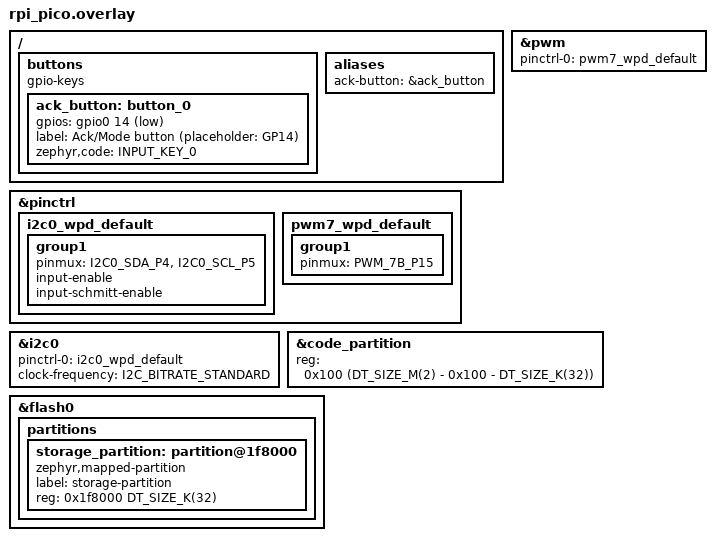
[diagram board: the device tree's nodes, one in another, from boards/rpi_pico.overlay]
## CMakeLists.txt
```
# Objetivo: arquivo de build da aplicação Zephyr.
#
# Responsabilidade: declarar os fontes compilados nesta etapa e os include paths
# compartilhados (include/ na raiz do repositório, ver docs/ARCHITECTURE.md, Diagrama
# Extra "Estrutura do Projeto").
#
# Dependências: $ENV{ZEPHYR_BASE} — exportado pelo ambiente West após `west update`
# (ver west.yml na raiz do repositório).
#
# Quem utiliza: comando `west build -b rpi_pico app`, executado a partir da raiz do
# workspace West (não da raiz deste repositório).
#
# Como testar: west build -b rpi_pico app && west build -t menuconfig (inspecionar
# símbolos resolvidos).
#
# Possíveis evoluções: nenhum módulo/infra pendente de add_subdirectory — tudo previsto
# em docs/ARCHITECTURE.md (Seção 6, Diagrama Extra "Arquitetura ZBus") existe a partir
# da Etapa 10.

cmake_minimum_required(VERSION 3.20.0)

find_package(Zephyr REQUIRED HINTS $ENV{ZEPHYR_BASE})
project(wpd_wearable_postura)

add_subdirectory(src/zbus)
add_subdirectory(src/logging)
add_subdirectory(src/modules/button)
add_subdirectory(src/modules/notification)
add_subdirectory(src/modules/posture_engine)
add_subdirectory(src/modules/shell)
add_subdirectory(src/modules/settings)

target_sources(app PRIVATE src/main.c)

target_include_directories(app PRIVATE
  ${CMAKE_CURRENT_SOURCE_DIR}/../include
  ${CMAKE_CURRENT_SOURCE_DIR}/src/zbus
)
```

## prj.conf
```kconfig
# Objetivo: configuração Kconfig das Etapas 2 (infraestrutura) e 3 (canais ZBus) — liga
# os subsistemas exigidos pela arquitetura (docs/ARCHITECTURE.md, Restrição 3.6 e
# RF06/RF07) sem ainda registrar nenhum handler de negócio (comando de Shell, schema de
# Settings, callback de Input, observer de canal). Cada subsistema é apenas "ligado e
# verificado pronto" em src/main.c.
#
# Responsabilidade: habilitar Logging (Etapa 1), Shell, Settings+NVS, Input (botão via
# gpio-keys), I2C (barramento do futuro IMU), PWM (motor de vibração) e ZBus (Etapa 3).
#
# Dependências: CONFIG_GPIO já vem =y do defconfig do board (rpi_pico_defconfig) — não
# precisa ser repetido aqui. Threads/Timers/Workqueues (k_thread, k_timer, k_work) são
# APIs do kernel Zephyr sempre presentes, sem Kconfig de habilitação própria; não há
# thread de aplicação real nesta etapa (sensor_thread/posture_thread/notification
# listener nascem na Etapa 4, junto com os módulos que as justificam) — CONFIG_THREAD_*
# abaixo só habilita introspecção via Shell das threads já existentes no kernel.
#
# Como testar: west build -b rpi_pico app -- a imagem deve subir, inicializar Settings
# (sem handlers, é um no-op válido), confirmar via log que i2c0/pwm/buttons/led0 estão
# "ready", e o shell deve responder ao comando `kernel threads` e `settings` na UART.
#
# Etapa 3 (canais ZBus): CONFIG_ZBUS=y liga o barramento. RNF02/Restrição 3
# (memória restrita, evitar alocação dinâmica) motivou desligar
# CONFIG_ZBUS_PREFER_DYNAMIC_ALLOCATION — os canais em si (ZBUS_CHAN_DEFINE) já são
# estáticos independente desta opção; ela só afeta funcionalidades que não usamos ainda
# (ZBUS_MSG_SUBSCRIBER/listener assíncrono). CONFIG_ZBUS_CHANNEL_NAME/OBSERVER_NAME
# habilitam nomes legíveis em log/debug, custo de Flash desprezível.
#
# Próxima etapa (Etapa 4) adicionará aqui os Kconfig específicos de cada módulo
# (app/src/modules/*), conforme forem implementados.

CONFIG_LOG=y
CONFIG_LOG_MODE_DEFERRED=y

CONFIG_SHELL=y

CONFIG_SETTINGS=y
CONFIG_FLASH=y
CONFIG_FLASH_MAP=y
CONFIG_NVS=y
CONFIG_SETTINGS_SHELL=y

CONFIG_INPUT=y
CONFIG_I2C=y
CONFIG_PWM=y

CONFIG_THREAD_NAME=y
CONFIG_THREAD_MONITOR=y

CONFIG_ZBUS=y
CONFIG_ZBUS_PREFER_DYNAMIC_ALLOCATION=n
CONFIG_ZBUS_CHANNEL_NAME=y
CONFIG_ZBUS_OBSERVER_NAME=y
```

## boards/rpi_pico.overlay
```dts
/*
 * Overlay de devicetree para Raspberry Pi Pico (RP2040) — Wearable de Correção de Postura.
 *
 * Objetivo: reservar, no nível de hardware, os periféricos previstos em
 * docs/ARCHITECTURE.md (Seção 7 "Identificação dos Periféricos") que ainda não têm
 * driver/consumidor concreto:
 *   - i2c0: barramento do futuro IMU (sensor ainda não escolhido — ver ADR 0002).
 *   - botão de ack/modo (gpio-keys).
 *   - canal PWM do motor de vibração.
 *
 * Responsabilidade: única fonte de verdade sobre pinagem física desta placa.
 * Dependências: dt-bindings de GPIO, I2C e pinctrl do RP2040 (fornecidos pelo módulo
 * hal_rpi_pico, importado via west.yml).
 * Quem utiliza: drivers/sensor/* (Etapa 4), app/src/modules/button (Etapa 4),
 *               app/src/modules/notification (Etapa 7 redefinida — ver ADR 0001).
 *
 * PLACEHOLDERS DE PINAGEM (combinados com o usuário na Etapa 1, ajustáveis em 1 linha
 * quando a fiação física definitiva for confirmada — nenhum módulo de software depende
 * do número do pino, apenas do alias/label):
 *   - I2C0 SDA/SCL -> GP4 / GP5
 *   - Botão de ack/modo -> GP14
 *   - PWM do motor de vibração -> GP15 (slice 7, canal B)
 *
 * Macros de pinmux confirmadas contra
 * zephyr/include/zephyr/dt-bindings/pinctrl/rpi-pico-pinctrl-common.h (workspace real):
 * I2C0_SDA_P4, I2C0_SCL_P5, PWM_7B_P15 (não "PWM_B7_P15" — nome corrigido após o
 * primeiro `west build`, que falhou com "expected number or parenthesized expression"
 * na linha do pinmux do PWM).
 *
 * Etapa 2 (infraestrutura): o binding "gpio-keys" é consumido pelo subsistema de Input
 * do Zephyr (drivers/input/input_gpio_keys.c, CONFIG_INPUT + CONFIG_INPUT_GPIO_KEYS), não
 * por leitura direta de GPIO. Esse driver exige a propriedade `zephyr,code` em cada botão
 * (DT_PROP sem fallback) — ausente na Etapa 1 porque CONFIG_INPUT estava desligado e o
 * driver nunca era compilado contra este overlay. Adicionada agora que CONFIG_INPUT=y.
 * O código semântico real (ack/reset/modo) só é interpretado em software na Etapa 4
 * (button_module) — aqui é só o requisito mínimo do binding de hardware.
 */

#include <zephyr/dt-bindings/gpio/gpio.h>
#include <zephyr/dt-bindings/i2c/i2c.h>
#include <zephyr/dt-bindings/pinctrl/rpi-pico-rp2040-pinctrl.h>
#include <zephyr/dt-bindings/input/input-event-codes.h>

/ {
	buttons: buttons {
		compatible = "gpio-keys";

		ack_button: button_0 {
			gpios = <&gpio0 14 (GPIO_PULL_UP | GPIO_ACTIVE_LOW)>;
			label = "Ack/Mode button (placeholder: GP14)";
			zephyr,code = <INPUT_KEY_0>;
		};
	};

	aliases {
		ack-button = &ack_button;
	};
};

&pinctrl {
	/* Estados de pinctrl próprios da aplicação — isolados dos defaults do board file
	 * para não colidir com nomes que o board já possa definir.
	 */
	i2c0_wpd_default: i2c0_wpd_default {
		group1 {
			pinmux = <I2C0_SDA_P4>, <I2C0_SCL_P5>;
			input-enable;
			input-schmitt-enable;
		};
	};

	pwm7_wpd_default: pwm7_wpd_default {
		group1 {
			pinmux = <PWM_7B_P15>;
		};
	};
};

&i2c0 {
	status = "okay";
	pinctrl-0 = <&i2c0_wpd_default>;
	pinctrl-names = "default";
	clock-frequency = <I2C_BITRATE_STANDARD>;
	/* Nenhum nó de sensor concreto ainda: o modelo do IMU não foi escolhido (ADR 0002).
	 * Adicionado quando o driver out-of-tree for implementado (Etapa 4).
	 */
};

/* RP2040 tem um único controlador PWM (`pwm`, label do SoC) multiplexando 8 slices x 2
 * canais (A/B) — não há node "pwm7" por slice. O canal é selecionado em tempo de uso via
 * pwm-cells: <&pwm CHANNEL PERIOD FLAGS>, com CHANNEL = slice*2 + (0=A, 1=B).
 * GP15 = slice 7 canal B (PWM_7B_P15) -> CHANNEL = 7*2+1 = 15.
 */
&pwm {
	status = "okay";
	pinctrl-0 = <&pwm7_wpd_default>;
	pinctrl-names = "default";
	/* Nenhum binding de atuador ainda: o motor de vibração será consumido diretamente
	 * pela Sensor/PWM API dentro do notification_module (Etapa 7 redefinida, ADR 0001),
	 * não por um node de devicetree genérico tipo "pwm-leds".
	 */
};

/* Etapa 2 (infraestrutura): partição de flash dedicada ao backend NVS do subsistema
 * Settings (RF07/RNF05). O board rpi_pico não define uma "storage_partition" própria —
 * o flash inteiro após o bootloader é um único `code_partition` read-only. Reservamos os
 * últimos 32 KiB (8 setores de 4 KiB, o erase-block-size do driver flash_rpi_pico) para
 * NVS, encolhendo `code_partition` na mesma medida. A aplicação atual (~26 KiB) fica
 * folgada dentro do novo tamanho de `code_partition` (~2 MiB - 32 KiB).
 */
&code_partition {
	reg = <0x100 (DT_SIZE_M(2) - 0x100 - DT_SIZE_K(32))>;
};

&flash0 {
	partitions {
		storage_partition: partition@1f8000 {
			compatible = "zephyr,mapped-partition";
			label = "storage-partition";
			reg = <0x1f8000 DT_SIZE_K(32)>;
		};
	};
};
```

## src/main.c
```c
/*
 * Objetivo: ponto de entrada do firmware.
 *
 * Nesta etapa (9 — settings), `settings_load()` passa a carregar `chan_config` de
 * verdade a partir da NVS (handler da subárvore "wpd" em src/modules/settings) — antes
 * disso era um no-op válido, sem nenhum handler registrado. main() continua sem saber que
 * Settings existe: ele só chama `settings_subsys_init()`/`settings_load()`, e é o
 * próprio módulo `settings` (via `SETTINGS_STATIC_HANDLER_DEFINE`) que se registra e
 * publica em `chan_config` quando o carregamento termina. Resta em main() apenas
 * `i2c0`, ainda sem módulo dono (sensor não escolhido, ADR 0002).
 *
 * Responsabilidade: orquestração de boot; bring-up do que ainda não tem módulo dono
 * (`i2c0`); smoke test de integração entre os módulos já existentes (Etapa 6).
 * Dependências: Logging, Settings (zephyr/settings/settings.h), Device Model
 * (zephyr/device.h), ZBus (src/zbus/zbus_channels.h).
 * Quem chama: o kernel Zephyr, após a inicialização dos drivers via SYS_INIT.
 * Quem utiliza: ninguém (é o entry point da aplicação).
 *
 * Como testar: west build -b rpi_pico app && flashar via UF2/picotool; abrir um
 * terminal serial na UART0 (115200 8N1) e confirmar, na ordem: mensagem de boot, status
 * "ready" de i2c0, resultado do settings_load(), smoke test de `chan_system_status`
 * e o smoke test de pipeline (deve terminar em GOOD, sem erro, e acionar
 * brevemente LED+motor de vibração durante o estado BAD sintético). Pressionar o botão
 * físico deve gerar log do módulo `button` seguido do módulo `posture_engine`.
 *
 * Possíveis evoluções: quando o driver do IMU existir (ADR 0002), o check de `i2c0`
 * também migra para o futuro sensor_driver e main() fica só com Settings + os smoke
 * tests de ZBus.
 */

#include <stdbool.h>

#include <zephyr/kernel.h>
#include <zephyr/logging/log.h>
#include <zephyr/device.h>
#include <zephyr/devicetree.h>
#include <zephyr/settings/settings.h>

#include "zbus_channels.h"

LOG_MODULE_REGISTER(main, CONFIG_LOG_DEFAULT_LEVEL);

static const struct device *const i2c0_dev = DEVICE_DT_GET(DT_NODELABEL(i2c0));

static void check_device_ready(const struct device *dev, const char *name)
{
	if (device_is_ready(dev)) {
		LOG_INF("%s: ready", name);
	} else {
		LOG_ERR("%s: NOT ready", name);
	}
}

static void zbus_smoke_test(void)
{
	struct wpd_system_status_msg tx = { .status = WPD_SYSTEM_STATUS_OK };
	struct wpd_system_status_msg rx = { 0 };
	int rc;

	rc = zbus_chan_pub(&chan_system_status, &tx, K_MSEC(100));
	if (rc != 0) {
		LOG_ERR("zbus: falha ao publicar em chan_system_status (rc=%d)", rc);
		return;
	}

	rc = zbus_chan_read(&chan_system_status, &rx, K_MSEC(100));
	if (rc != 0 || rx.status != WPD_SYSTEM_STATUS_OK) {
		LOG_ERR("zbus: falha ao ler chan_system_status (rc=%d, status=%d)", rc,
			rx.status);
		return;
	}

	LOG_INF("zbus: smoke test OK (publish+read em chan_system_status)");
}

/* Publica uma amostra sintética em chan_sensor_data e devolve o estado postural
 * resultante (lido de chan_posture_state). Retorna false só em erro de zbus -- não
 * julga se o estado lido é o esperado (isso é responsabilidade de quem chama).
 */
static bool publish_sample(int32_t angle_mdeg, enum wpd_posture_state *state_out)
{
	struct wpd_sensor_sample sample = { .angle_mdeg = angle_mdeg };
	struct wpd_posture_state_msg state;
	int rc;

	rc = zbus_chan_pub(&chan_sensor_data, &sample, K_MSEC(100));
	if (rc != 0) {
		LOG_ERR("pipeline: falha ao publicar chan_sensor_data (rc=%d)", rc);
		return false;
	}

	rc = zbus_chan_read(&chan_posture_state, &state, K_MSEC(100));
	if (rc != 0) {
		LOG_ERR("pipeline: falha ao ler chan_posture_state (rc=%d)", rc);
		return false;
	}

	*state_out = state.state;
	return true;
}

static void posture_pipeline_smoke_test(void)
{
	enum wpd_posture_state state;
	struct wpd_posture_config cfg;

	/* A partir da Etapa 9, chan_config pode ter sido carregado da NVS com um valor
	 * diferente do default (ex.: usuario configurou via `wpd config threshold` numa
	 * sessao anterior) -- ler o limiar atual em vez de assumir o default evita este
	 * smoke test falhar sozinho so porque a configuracao persistida mudou.
	 */
	int rc = zbus_chan_read(&chan_config, &cfg, K_MSEC(100));

	if (rc != 0) {
		LOG_ERR("pipeline: falha ao ler chan_config (rc=%d)", rc);
		return;
	}

	/* Margem de 15000 mdeg acima do limiar atual: garante que a amostra sintetica
	 * excede o limiar sem depender do valor exato (default ou persistido).
	 */
	int32_t bad_angle_mdeg = cfg.threshold_mdeg + 15000;

	if (!publish_sample(bad_angle_mdeg, &state) || state != WPD_POSTURE_BAD) {
		LOG_ERR("pipeline: esperava BAD apos amostra de %d mdeg (limiar=%d), obteve %d",
			bad_angle_mdeg, cfg.threshold_mdeg, state);
		return;
	}

	/* Volta a 0 grau -- mas o filtro de posture_engine é uma média móvel exponencial
	 * (retém ~75% do valor anterior a cada amostra), então uma única amostra "boa"
	 * não é suficiente para o ângulo filtrado cruzar de volta o limiar. Publicamos
	 * algumas amostras seguidas até o filtro assentar (sem julgar as intermediárias
	 * como erro), e só então checamos GOOD -- isso também cancela o timer de
	 * histerese armado pela amostra ruim acima (sem isso, o sistema "alertaria"
	 * sozinho ~30s depois, sem ninguém ter testado nada).
	 */
	for (int i = 0; i < 6; i++) {
		if (!publish_sample(0, &state)) {
			return;
		}
		if (state == WPD_POSTURE_GOOD) {
			break;
		}
	}

	if (state != WPD_POSTURE_GOOD) {
		LOG_ERR("pipeline: angulo filtrado nao assentou em GOOD apos 6 amostras");
		return;
	}

	LOG_INF("pipeline sensor->posture_engine->notification OK "
		"(GOOD->BAD->GOOD via amostras sinteticas)");
}

int main(void)
{
	LOG_INF("Wearable de Correcao de Postura - boot OK (Etapa 9: settings)");

	check_device_ready(i2c0_dev, "i2c0");

	int rc = settings_subsys_init();

	if (rc != 0) {
		LOG_ERR("settings_subsys_init falhou (rc=%d)", rc);
	} else {
		rc = settings_load();
		LOG_INF("settings: subsistema inicializado, settings_load rc=%d "
			"(handler wpd/* registrado - ver src/modules/settings)", rc);
	}

	zbus_smoke_test();
	posture_pipeline_smoke_test();

	return 0;
}
```
